AUTOSAR XML (schema 00051)
package /Components
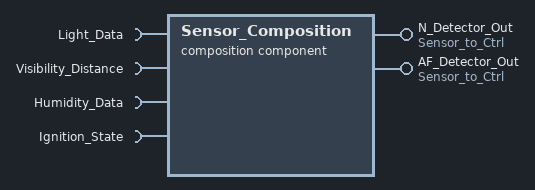
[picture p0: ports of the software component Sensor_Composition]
  composition sw component type Sensor_Composition
    4 x require port:
      Light_Data: required-interface=Light_Data
      Visibility_Distance: required-interface=Visibility_Distance
      Humidity_Data: required-interface=Humidity_Data
      Ignition_State: required-interface=Ignition_State
    provide port N_Detector_Out: provided-interface=Sensor_to_Ctrl
    provide port AF_Detector_Out: provided-interface=Sensor_to_Ctrl
    component AutomaticFog_Detector: type=AutomaticFog_Detector
    component Monitor: type=Monitor
    component Night_Detector: type=Night_Detector
    connect AutomaticFog_Detector.AF_Detector_In -> Monitor.AF_Detector_In
    connect Night_Detector.N_Detector_In -> Monitor.N_Detector_In
    delegate Monitor.N_Detector_Out <-> outer port N_Detector_Out
    delegate Monitor.AF_Detector_Out <-> outer port AF_Detector_Out
    delegate Night_Detector.Light_Data <-> outer port Light_Data
    delegate AutomaticFog_Detector.Visibility_Distance <-> outer port Visibility_Distance
    delegate AutomaticFog_Detector.Humidity_Data <-> outer port Humidity_Data
    delegate Night_Detector.Ignition_State <-> outer port Ignition_State
    delegate AutomaticFog_Detector.Ignition_State <-> outer port Ignition_State
